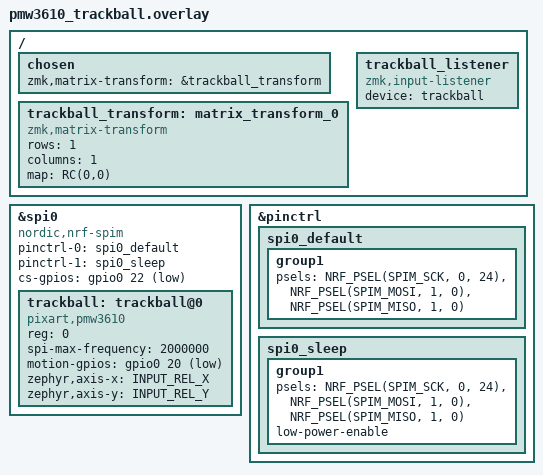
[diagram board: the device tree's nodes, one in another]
#include <dt-bindings/gpio/gpio.h>
#include <dt-bindings/input/input-event-codes.h>
#include <dt-bindings/pinctrl/nrf-pinctrl.h>
#include <dt-bindings/zmk/matrix_transform.h>

/ {
    chosen {
        zmk,matrix-transform = &trackball_transform;
    };

    trackball_transform: matrix_transform_0 {
        compatible = "zmk,matrix-transform";
        rows = <1>;
        columns = <1>;
        map = <RC(0,0)>;
    };

    trackball_listener {
        compatible = "zmk,input-listener";
        device = <&trackball>;
    };
};

&spi0 {
    compatible = "nordic,nrf-spim";
    status = "okay";
    pinctrl-0 = <&spi0_default>;
    pinctrl-1 = <&spi0_sleep>;
    pinctrl-names = "default", "sleep";
    cs-gpios = <&gpio0 22 GPIO_ACTIVE_LOW>;

    trackball: trackball@0 {
        compatible = "pixart,pmw3610";
        reg = <0>;
        status = "okay";
        spi-max-frequency = <2000000>;
        motion-gpios = <&gpio0 20 (GPIO_ACTIVE_LOW | GPIO_PULL_UP)>;
        zephyr,axis-x = <INPUT_REL_X>;
        zephyr,axis-y = <INPUT_REL_Y>;
    };
};

&pinctrl {
    spi0_default: spi0_default {
        group1 {
            psels = <NRF_PSEL(SPIM_SCK, 0, 24)>,
                    <NRF_PSEL(SPIM_MOSI, 1, 0)>,
                    <NRF_PSEL(SPIM_MISO, 1, 0)>;
        };
    };

    spi0_sleep: spi0_sleep {
        group1 {
            psels = <NRF_PSEL(SPIM_SCK, 0, 24)>,
                    <NRF_PSEL(SPIM_MOSI, 1, 0)>,
                    <NRF_PSEL(SPIM_MISO, 1, 0)>;
            low-power-enable;
        };
    };
};
